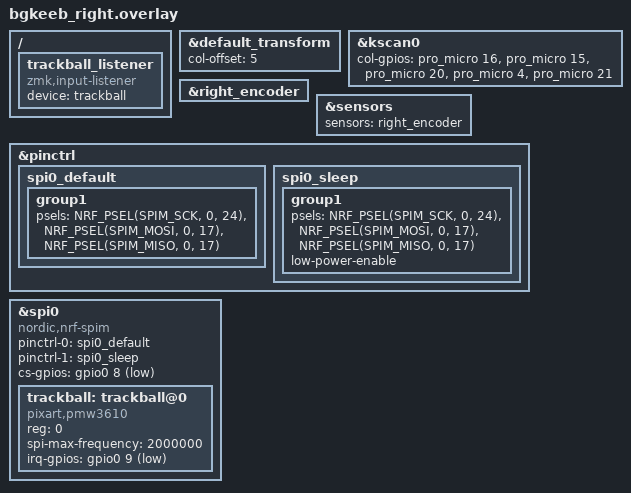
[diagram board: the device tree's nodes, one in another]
#include "bgkeeb.dtsi" // Notice that the main dtsi files are included in the overlay.

&default_transform { // The matrix transform for this board is 5 columns over because the left half is 5 columns wide according to the matrix.
    col-offset = <5>;
};

&kscan0 {
    // #define MATRIX_ROW_PINS { F6, D7, B3, E6 }     == { 19, 6, 14, 7 }
    // #define MATRIX_COL_PINS { F4, D4, F5, B1, B2 } == { 21, 4, 20, 15, 16 }
    // columns reversed
    col-gpios
        = <&pro_micro 16 GPIO_ACTIVE_HIGH> // col1 in the schematic
        , <&pro_micro 15 GPIO_ACTIVE_HIGH>  // col2 in the schematic
        , <&pro_micro 20 GPIO_ACTIVE_HIGH> // col3 in the schematic
        , <&pro_micro 4 GPIO_ACTIVE_HIGH> // col4 in the schematic
        , <&pro_micro 21 GPIO_ACTIVE_HIGH> // col5 in the schematic
        ;
};

&right_encoder {
    status = "okay";
};

&sensors {
    sensors = <&right_encoder>;
};

/* PMW3610 Trackball Configuration */
&pinctrl {
    spi0_default: spi0_default {
        group1 {
            psels = <NRF_PSEL(SPIM_SCK, 0, 24)>,
                <NRF_PSEL(SPIM_MOSI, 0, 17)>,
                <NRF_PSEL(SPIM_MISO, 0, 17)>;
        };
    };

    spi0_sleep: spi0_sleep {
        group1 {
            psels = <NRF_PSEL(SPIM_SCK, 0, 24)>,
                <NRF_PSEL(SPIM_MOSI, 0, 17)>,
                <NRF_PSEL(SPIM_MISO, 0, 17)>;
            low-power-enable;
        };
    };
};

&spi0 {
    status = "okay";
    compatible = "nordic,nrf-spim";
    pinctrl-0 = <&spi0_default>;
    pinctrl-1 = <&spi0_sleep>;
    pinctrl-names = "default", "sleep";
    cs-gpios = <&gpio0 8 GPIO_ACTIVE_LOW>;

    trackball: trackball@0 {
        status = "okay";
        compatible = "pixart,pmw3610";
        reg = <0>;
        spi-max-frequency = <2000000>;
        irq-gpios = <&gpio0 9 (GPIO_ACTIVE_LOW | GPIO_PULL_UP)>;
    };
};

/ {
    trackball_listener {
        compatible = "zmk,input-listener";
        device = <&trackball>;
    };
};
